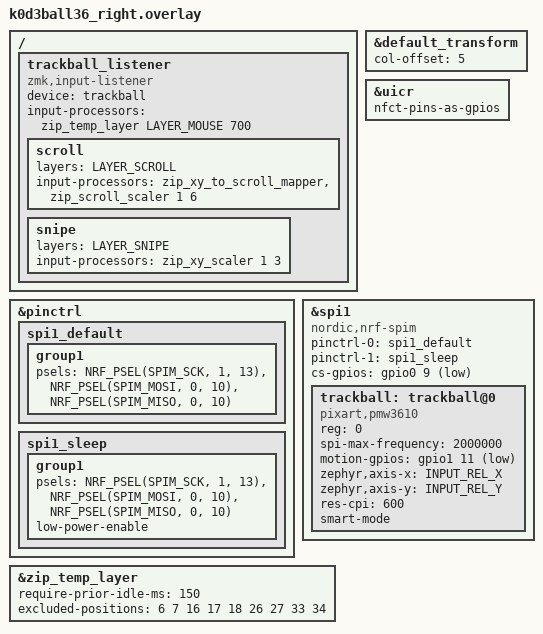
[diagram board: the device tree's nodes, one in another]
/*
 * Right half (split central, 15 finger + 2 thumb keys, carries the PMW3610
 * trackball sensor for the 19.05 mm ball).
 *
 * Row and column pins are shared with the left half and live in k0d3ball36.dtsi
 * (COL0..COL4 = pro_micro 4..8, ROW0..ROW3 = pro_micro 21, 20, 19, 18). Sensor:
 *   TB_SCLK  pro_micro 15 = P1.13
 *   TB_SDIO  pro_micro 16 = P0.10  (3-wire SPI: MOSI and MISO on the same pin)
 *   TB_NCS   pro_micro 10 = P0.09
 *   TB_MOT   pro_micro 14 = P1.11
 */

#include "k0d3ball36.dtsi"
#include <dt-bindings/input/input-event-codes.h>
#include <input/processors.dtsi>

#define LAYER_MOUSE  4
#define LAYER_SCROLL 5
#define LAYER_SNIPE  6

&default_transform {
    col-offset = <5>;
};

/* P0.09 / P0.10 are the NFC antenna pins; use them as plain GPIO. */
&uicr {
    nfct-pins-as-gpios;
};

&pinctrl {
    spi1_default: spi1_default {
        group1 {
            psels = <NRF_PSEL(SPIM_SCK, 1, 13)>,
                    <NRF_PSEL(SPIM_MOSI, 0, 10)>,
                    <NRF_PSEL(SPIM_MISO, 0, 10)>;
        };
    };

    spi1_sleep: spi1_sleep {
        group1 {
            psels = <NRF_PSEL(SPIM_SCK, 1, 13)>,
                    <NRF_PSEL(SPIM_MOSI, 0, 10)>,
                    <NRF_PSEL(SPIM_MISO, 0, 10)>;
            low-power-enable;
        };
    };
};

&spi1 {
    status = "okay";
    compatible = "nordic,nrf-spim";
    pinctrl-0 = <&spi1_default>;
    pinctrl-1 = <&spi1_sleep>;
    pinctrl-names = "default", "sleep";
    cs-gpios = <&gpio0 9 GPIO_ACTIVE_LOW>;

    trackball: trackball@0 {
        status = "okay";
        compatible = "pixart,pmw3610";
        reg = <0>;
        spi-max-frequency = <2000000>;
        motion-gpios = <&gpio1 11 (GPIO_ACTIVE_LOW | GPIO_PULL_UP)>;
        zephyr,axis-x = <INPUT_REL_X>;
        zephyr,axis-y = <INPUT_REL_Y>;
        /* 19.05 mm ball. The sensor counts surface travel, and a rigid sphere moves
         * its surface by the same mm at the sensor as under the thumb whatever its
         * size, so counts per mm of thumb travel do not change. What changes is the
         * stroke: the thumb runs off a smaller sphere sooner and the light ball does
         * not coast after a flick, so each stroke moves less surface. To cover the
         * same screen distance per stroke the 19 mm ball needs about 30 percent more
         * CPI than the 25 mm setup (400). Start at 600 and tune, see
         * issues/fw-cpi-tuning-19mm.md. */
        res-cpi = <600>;
        smart-mode;
        /* Flip these if the cursor moves the wrong way after assembly. */
        // invert-x;
        // invert-y;
    };
};

/* Keys that keep the auto mouse layer alive while it is active (mouse buttons,
 * scroll and snipe modifiers on the right half). Positions follow the matrix
 * transform order in k0d3ball36.dtsi (35 keys): 6 7 = scroll/snipe layer keys,
 * 16 17 18 = left/right/middle click, 26 27 = back/forward, 33 34 = the two
 * right thumb keys. */
&zip_temp_layer {
    require-prior-idle-ms = <150>;
    excluded-positions = <6 7 16 17 18 26 27 33 34>;
};

/ {
    trackball_listener: trackball_listener {
        compatible = "zmk,input-listener";
        device = <&trackball>;
        input-processors = <&zip_temp_layer LAYER_MOUSE 700>;

        scroll {
            layers = <LAYER_SCROLL>;
            input-processors = <&zip_xy_to_scroll_mapper>, <&zip_scroll_scaler 1 6>;
        };

        snipe {
            layers = <LAYER_SNIPE>;
            input-processors = <&zip_xy_scaler 1 3>;
        };
    };
};
